# ATSAM4E16E device description
Architecture: CORTEX-M4; Family: SAM4; Series: SAM4E
Registers are 32-bit, read-write, no defined reset value unless marked. A register's access mark holds for its fields unless they carry their own. Offsets are from the block's base; [hi:lo] are bit positions; {n}, {i} and the like mark numbered series.

## CRCCU — Cyclic Redundancy Check Calculation Unit
Instances: CRCCU 0x40044000
0x00 CRCCU_DSCR — CRCCU Descriptor Base Register
  [31:9] DSCR — Descriptor Base Address
0x08 CRCCU_DMA_EN wo — CRCCU DMA Enable Register
  [0] DMAEN — DMA Enable Register
0x0C CRCCU_DMA_DIS wo — CRCCU DMA Disable Register
  [0] DMADIS — DMA Disable Register
0x10 CRCCU_DMA_SR ro — CRCCU DMA Status Register
  [0] DMASR — DMA Status Register
0x14 CRCCU_DMA_IER wo — CRCCU DMA Interrupt Enable Register
  [0] DMAIER — Interrupt Enable register
0x18 CRCCU_DMA_IDR wo — CRCCU DMA Interrupt Disable Register
  [0] DMAIDR — Interrupt Disable register
0x1C CRCCU_DMA_IMR ro — CRCCU DMA Interrupt Mask Register
  [0] DMAIMR — Interrupt Mask Register
0x20 CRCCU_DMA_ISR ro — CRCCU DMA Interrupt Status Register
  [0] DMAISR — Interrupt Status register
0x34 CRCCU_CR wo — CRCCU Control Register
  [0] RESET — CRC Computation Reset
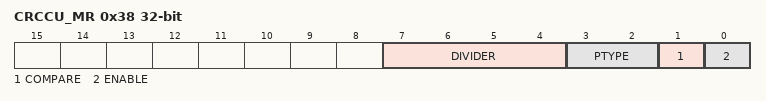
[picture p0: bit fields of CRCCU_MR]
0x38 CRCCU_MR — CRCCU Mode Register
  [7:4] DIVIDER — Request Divider
  [3:2] PTYPE — Primitive Polynomial
    0=CCITT8023 (Polynom 0x04C11DB7); 1=CASTAGNOLI (Polynom 0x1EDC6F41); 2=CCITT16 (Polynom 0x1021)
  [1] COMPARE — CRC Compare
  [0] ENABLE — CRC Enable
0x3C CRCCU_SR ro — CRCCU Status Register
  [31:0] CRC — Cyclic Redundancy Check Value
0x40 CRCCU_IER wo — CRCCU Interrupt Enable Register
  [0] ERRIER — CRC Error Interrupt Enable
0x44 CRCCU_IDR wo — CRCCU Interrupt Disable Register
  [0] ERRIDR — CRC Error Interrupt Disable
0x48 CRCCU_IMR ro — CRCCU Interrupt Mask Register
  [0] ERRIMR — CRC Error Interrupt Mask
0x4C CRCCU_ISR ro — CRCCU Interrupt Status Register
  [0] ERRISR — CRC Error Interrupt Status

## EFC — Embedded Flash Controller
Instances: EFC 0x400E0A00
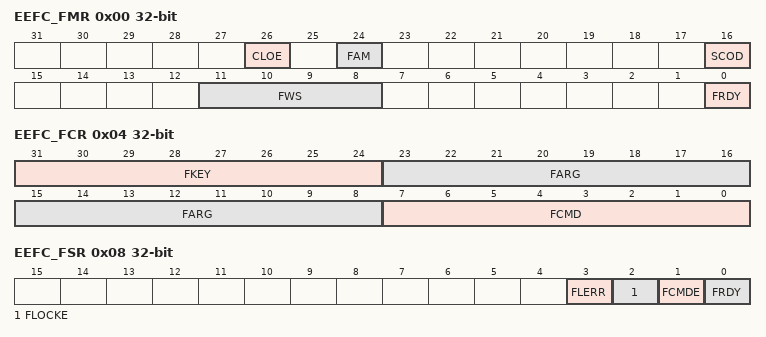
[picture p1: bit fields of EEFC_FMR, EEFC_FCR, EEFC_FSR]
0x00 EEFC_FMR — EEFC Flash Mode Register
  [26] CLOE — Code Loops Optimization Enable
  [24] FAM — Flash Access Mode
  [16] SCOD — Sequential Code Optimization Disable
  [11:8] FWS — Flash Wait State
  [0] FRDY — Ready Interrupt Enable
0x04 EEFC_FCR wo — EEFC Flash Command Register
  [31:24] FKEY — Flash Writing Protection Key
    90=PASSWD (The 0x5A value enables the command defined by the bits of the register. If the field is written with a different value, the write is not performed and no action is started.)
  [23:8] FARG — Flash Command Argument
  [7:0] FCMD — Flash Command
    0=GETD (Get Flash Descriptor); 1=WP (Write page); 2=WPL (Write page and lock); 3=EWP (Erase page and write page); 4=EWPL (Erase page and write page then lock); 5=EA (Erase all); 7=EPA (Erase Pages); 8=SLB (Set Lock Bit); 9=CLB (Clear Lock Bit); 10=GLB (Get Lock Bit); 11=SGPB (Set GPNVM Bit); 12=CGPB (Clear GPNVM Bit); 13=GGPB (Get GPNVM Bit); 14=STUI (Start Read Unique Identifier); 15=SPUI (Stop Read Unique Identifier); 16=GCALB (Get CALIB Bit); 17=ES (Erase Sector); 18=WUS (Write User Signature); 19=EUS (Erase User Signature); 20=STUS (Start Read User Signature); 21=SPUS (Stop Read User Signature)
0x08 EEFC_FSR ro — EEFC Flash Status Register
  [3] FLERR — Flash Error Status
  [2] FLOCKE — Flash Lock Error Status
  [1] FCMDE — Flash Command Error Status
  [0] FRDY — Flash Ready Status
0x0C EEFC_FRR ro — EEFC Flash Result Register
  [31:0] FVALUE — Flash Result Value

## GPBR — General Purpose Backup Register
Instances: GPBR 0x400E1890
{0x0+4i} SYS_GPBR{i} (i=0..19) — General Purpose Backup Register {i}
  [31:0] GPBR_VALUE — Value of GPBR x

## MATRIX — AHB Bus Matrix
Instances: MATRIX 0x400E0200
{0x0+4i} MATRIX_MCFG{i} (i=0..15) — Master Configuration Register {i}
  [2:0] ULBT — Undefined Length Burst Type
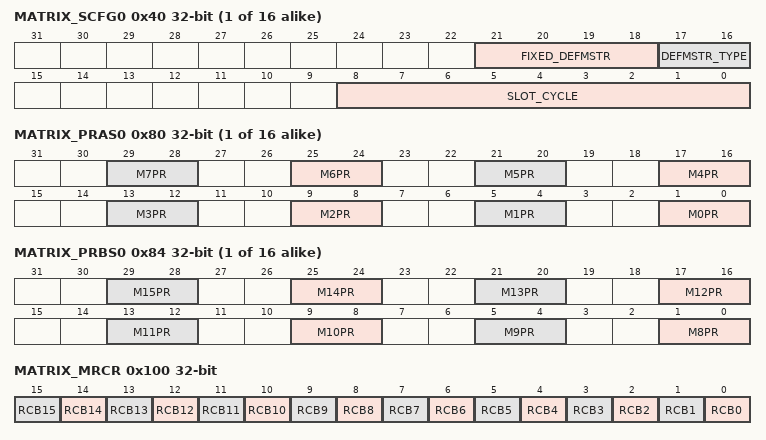
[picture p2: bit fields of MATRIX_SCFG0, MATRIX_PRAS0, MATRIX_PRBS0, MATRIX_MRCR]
{0x40+4i} MATRIX_SCFG{i} (i=0..15) — Slave Configuration Register {i}
  [21:18] FIXED_DEFMSTR — Fixed Default Master
  [17:16] DEFMSTR_TYPE — Default Master Type
  [8:0] SLOT_CYCLE — Maximum Bus Grant Duration for Masters
{0x80+8i} MATRIX_PRAS{i} (i=0..15) — Priority Register A for Slave {i}
  [4n+1:4n] M{n}PR (n=0..7) — Master {n} Priority
{0x84+8i} MATRIX_PRBS{i} (i=0..15) — Priority Register B for Slave {i}
  [4n-31:4n-32] M{n}PR (n=8..15) — Master {n} Priority
0x100 MATRIX_MRCR — Master Remap Control Register
  [n] RCB{n} (n=0..15)
{0x110+4i} MATRIX_SFR{i} (i=0..15) — Special Function Register {i}
  [31:0] SFR — Special Function Register Fields
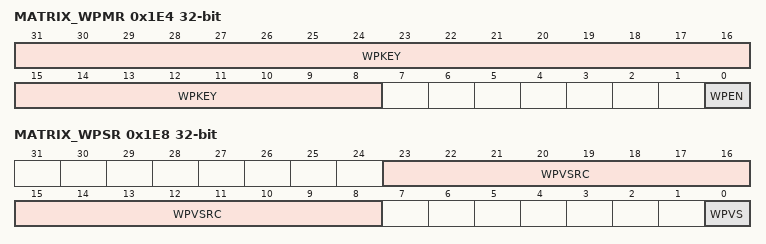
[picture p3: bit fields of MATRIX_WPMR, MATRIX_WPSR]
0x1E4 MATRIX_WPMR — Write Protect Mode Register
  [31:8] WPKEY — Write Protect KEY (Write-only)
  [0] WPEN — Write Protect Enable
0x1E8 MATRIX_WPSR ro — Write Protect Status Register
  [23:8] WPVSRC — Write Protect Violation Source
  [0] WPVS — Write Protect Violation Status
